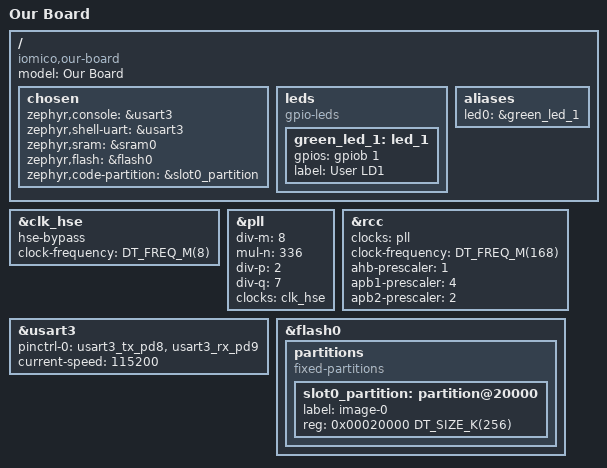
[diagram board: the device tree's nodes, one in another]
/*
 * SPDX-License-Identifier: Apache-2.0
 */

/dts-v1/;
#include <st/f4/stm32f429Xi.dtsi>
#include <st/f4/stm32f429zitx-pinctrl.dtsi>

/ {
	model = "Our Board";
	compatible = "iomico,our-board";

	chosen {
		zephyr,console = &usart3;
		zephyr,shell-uart = &usart3;
		zephyr,sram = &sram0;
		zephyr,flash = &flash0;
		zephyr,code-partition = &slot0_partition;
	};

	leds: leds {
		compatible = "gpio-leds";

		green_led_1: led_1 {
			gpios = <&gpiob 1 GPIO_ACTIVE_HIGH>;
			label = "User LD1";
		};
	};

	aliases {
		led0 = &green_led_1;
	};
};

&clk_hse {
	hse-bypass;
	clock-frequency = <DT_FREQ_M(8)>;
	status = "okay";
};

&pll {
	div-m = <8>;
	mul-n = <336>;
	div-p = <2>;
	div-q = <7>;
	clocks = <&clk_hse>;
	status = "okay";
};

&rcc {
	clocks = <&pll>;
	clock-frequency = <DT_FREQ_M(168)>;
	ahb-prescaler = <1>;
	apb1-prescaler = <4>;
	apb2-prescaler = <2>;
};

&usart3 {
	pinctrl-0 = <&usart3_tx_pd8 &usart3_rx_pd9>;
	pinctrl-names = "default";
	current-speed = <115200>;
	status = "okay";
};

&flash0 {
	partitions {
		compatible = "fixed-partitions";
		#address-cells = <1>;
		#size-cells = <1>;

		slot0_partition: partition@20000 {
			label = "image-0";
			reg = <0x00020000 DT_SIZE_K(256)>;
		};
	};
};
